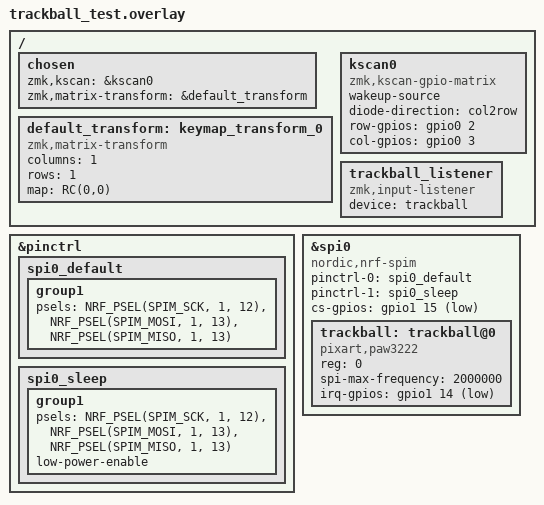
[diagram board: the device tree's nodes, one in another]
#include <dt-bindings/zmk/matrix_transform.h>

/ {
    chosen {
        zmk,kscan = &kscan0;
        zmk,matrix-transform = &default_transform;
    };

    default_transform: keymap_transform_0 {
        compatible = "zmk,matrix-transform";
        columns = <1>;
        rows = <1>;
        map = <RC(0,0)>;
    };

    kscan0: kscan0 {
        compatible = "zmk,kscan-gpio-matrix";
        wakeup-source;
        diode-direction = "col2row";
        row-gpios = <&gpio0 2 GPIO_ACTIVE_HIGH>;
        col-gpios = <&gpio0 3 GPIO_ACTIVE_HIGH>;
    };

    trackball_listener: trackball_listener {
        compatible = "zmk,input-listener";
        device = <&trackball>;
    };
};

&pinctrl {
    spi0_default: spi0_default {
        group1 {
            psels = <NRF_PSEL(SPIM_SCK, 1, 12)>,    // D7 = P1.12 (SCLK)
                    <NRF_PSEL(SPIM_MOSI, 1, 13)>,   // D8 = P1.13 (SDIO)
                    <NRF_PSEL(SPIM_MISO, 1, 13)>;   // D8 = P1.13 (SDIO兼用)
        };
    };

    spi0_sleep: spi0_sleep {
        group1 {
            psels = <NRF_PSEL(SPIM_SCK, 1, 12)>,
                    <NRF_PSEL(SPIM_MOSI, 1, 13)>,
                    <NRF_PSEL(SPIM_MISO, 1, 13)>;
            low-power-enable;
        };
    };
};

&spi0 {
    status = "okay";
    compatible = "nordic,nrf-spim";
    pinctrl-0 = <&spi0_default>;
    pinctrl-1 = <&spi0_sleep>;
    pinctrl-names = "default", "sleep";
    cs-gpios = <&gpio1 15 GPIO_ACTIVE_LOW>;   // D10 = P1.15 (CS)

    trackball: trackball@0 {
        status = "okay";
        compatible = "pixart,paw3222";
        reg = <0>;
        spi-max-frequency = <2000000>;
        irq-gpios = <&gpio1 14 (GPIO_ACTIVE_LOW | GPIO_PULL_UP)>;  // D9 = P1.14 (MOTION)
    };
};
